# ATSAMA5D27WLSOM1 device description
Architecture: CORTEX-A5; Family: SAMA5; Series: SAMA5D2
Registers are 32-bit, read-write, no defined reset value unless marked. A register's access mark holds for its fields unless they carry their own. Offsets are from the block's base; [hi:lo] are bit positions; lines under a group give offsets from that group; {n}, {i} and the like mark numbered series; 'fields as' and 'values as' point back to an identical list.

## ISC — Image Sensor Controller
Instances: ISC 0xF0008000
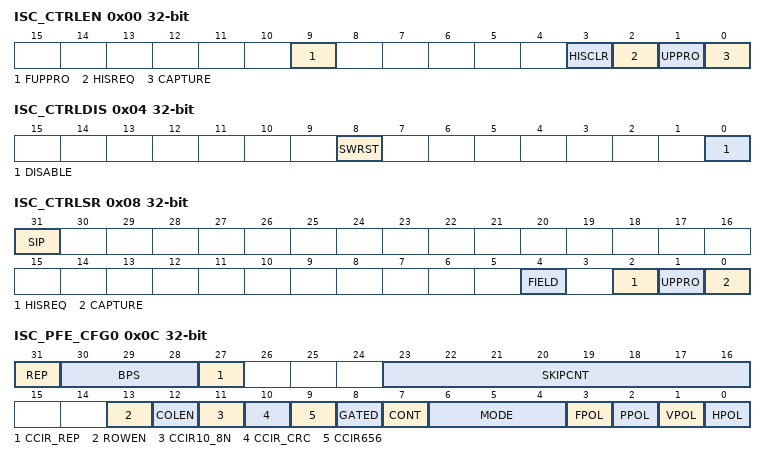
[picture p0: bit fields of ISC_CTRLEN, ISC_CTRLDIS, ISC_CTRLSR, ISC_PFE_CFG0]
0x00 ISC_CTRLEN wo — Control Enable Register
  [9] FUPPRO — Force Update Color Profile
  [3] HISCLR — Histogram Clear
  [2] HISREQ — Histogram Request
  [1] UPPRO — Update Profile
  [0] CAPTURE — Capture Input Stream Command
0x04 ISC_CTRLDIS wo — Control Disable Register
  [8] SWRST — Software Reset
  [0] DISABLE — Capture Disable
0x08 ISC_CTRLSR ro — Control Status Register
  [31] SIP — Synchronization In Progress
  [4] FIELD — Field Status (only relevant when the video stream is interlaced)
  [2] HISREQ — Histogram Request Pending
  [1] UPPRO — Profile Update Pending
  [0] CAPTURE — Capture pending
0x0C ISC_PFE_CFG0 — Parallel Front End Configuration 0 Register
  [31] REP — Up Multiply with Replication
  [30:28] BPS — Bits Per Sample
    0=TWELVE (12-bit input); 1=ELEVEN (11-bit input); 2=TEN (10-bit input); 3=NINE (9-bit input); 4=EIGHT (8-bit input)
  [27] CCIR_REP — CCIR Replication
  [23:16] SKIPCNT — Frame Skipping Counter
  [13] ROWEN — Row Cropping Enable
  [12] COLEN — Column Cropping Enable
  [11] CCIR10_8N — CCIR 10 bits or 8 bits
  [10] CCIR_CRC — CCIR656 CRC Decoder
  [9] CCIR656 — CCIR656 input mode
  [8] GATED — Gated input clock
  [7] CONT — Continuous Acquisition
  [6:4] MODE — Parallel Front End Mode
    0=PROGRESSIVE (Video source is progressive.); 1=DF_TOP (Video source is interlaced, two fields are captured starting with top field.); 2=DF_BOTTOM (Video source is interlaced, two fields are captured starting with bottom field.); 3=DF_IMMEDIATE (Video source is interlaced, two fields are captured immediately.); 4=SF_TOP (Video source is interlaced, one field is captured starting with the top field.); 5=SF_BOTTOM (Video source is interlaced, one field is captured starting with the bottom field.); 6=SF_IMMEDIATE (Video source is interlaced, one field is captured starting immediately.)
  [3] FPOL — Field Polarity
  [2] PPOL — Pixel Clock Polarity
  [1] VPOL — Vertical Synchronization Polarity
  [0] HPOL — Horizontal Synchronization Polarity
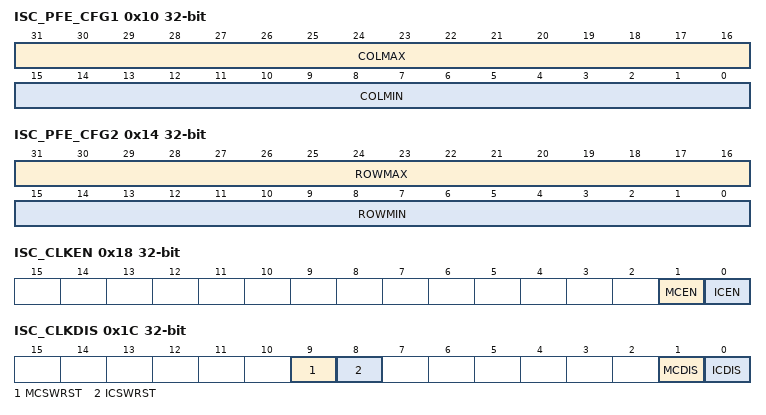
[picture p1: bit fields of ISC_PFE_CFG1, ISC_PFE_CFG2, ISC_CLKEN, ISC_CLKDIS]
0x10 ISC_PFE_CFG1 — Parallel Front End Configuration 1 Register
  [31:16] COLMAX — Column Maximum Limit
  [15:0] COLMIN — Column Minimum Limit
0x14 ISC_PFE_CFG2 — Parallel Front End Configuration 2 Register
  [31:16] ROWMAX — Row Maximum Limit
  [15:0] ROWMIN — Row Minimum Limit
0x18 ISC_CLKEN wo — Clock Enable Register
  [1] MCEN — Master Clock Enable
  [0] ICEN — ISP Clock Enable
0x1C ISC_CLKDIS wo — Clock Disable Register
  [9] MCSWRST — Master Clock Software Reset
  [8] ICSWRST — ISP Clock Software Reset
  [1] MCDIS — Master Clock Disable
  [0] ICDIS — ISP Clock Disable
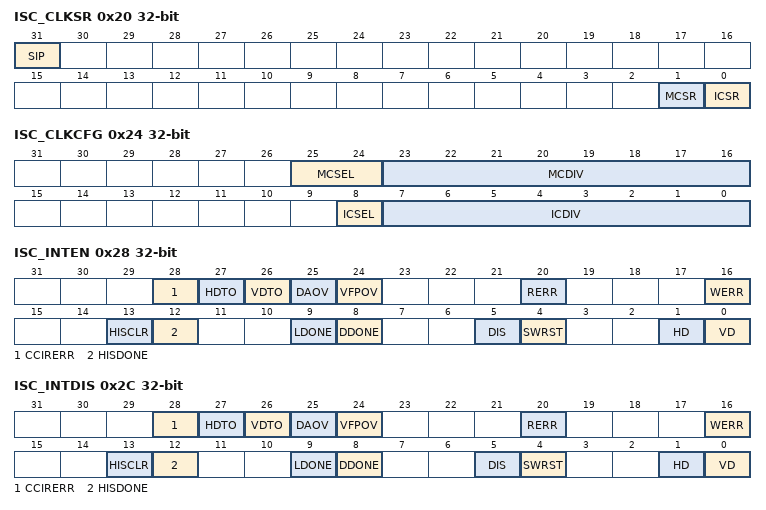
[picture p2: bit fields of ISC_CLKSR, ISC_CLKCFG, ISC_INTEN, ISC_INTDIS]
0x20 ISC_CLKSR ro — Clock Status Register
  [31] SIP — Synchronization In Progress
  [1] MCSR — Master Clock Status Register
  [0] ICSR — ISP Clock Status Register
0x24 ISC_CLKCFG — Clock Configuration Register
  [25:24] MCSEL — Master Clock Reference Clock Selection
  [23:16] MCDIV — Master Clock Divider
  [8] ICSEL — ISP Clock Selection
  [7:0] ICDIV — ISP Clock Divider
0x28 ISC_INTEN wo — Interrupt Enable Register
  [28] CCIRERR — CCIR Decoder Error Interrupt Enable
  [27] HDTO — Horizontal Synchronization Timeout Interrupt Enable
  [26] VDTO — Vertical Synchronization Timeout Interrupt Enable
  [25] DAOV — Data Overflow Interrupt Enable
  [24] VFPOV — Vertical Front Porch Overflow Interrupt Enable
  [20] RERR — Read Channel Error Interrupt Enable
  [16] WERR — Write Channel Error Interrupt Enable
  [13] HISCLR — Histogram Clear Interrupt Enable
  [12] HISDONE — Histogram Completed Interrupt Enable
  [9] LDONE — DMA List Done Interrupt Enable
  [8] DDONE — DMA Done Interrupt Enable
  [5] DIS — Disable Completed Interrupt Enable
  [4] SWRST — Software Reset Completed Interrupt Enable
  [1] HD — Horizontal Synchronization Detection Interrupt Enable
  [0] VD — Vertical Synchronization Detection Interrupt Enable
0x2C ISC_INTDIS wo — Interrupt Disable Register
  [28] CCIRERR — CCIR Decoder Error Interrupt Disable
  [27] HDTO — Horizontal Synchronization Timeout Interrupt Disable
  [26] VDTO — Vertical Synchronization Timeout Interrupt Disable
  [25] DAOV — Data Overflow Interrupt Disable
  [24] VFPOV — Vertical Front Porch Overflow Interrupt Disable
  [20] RERR — Read Channel Error Interrupt Disable
  [16] WERR — Write Channel Error Interrupt Disable
  [13] HISCLR — Histogram Clear Interrupt Disable
  [12] HISDONE — Histogram Completed Interrupt Disable
  [9] LDONE — DMA List Done Interrupt Disable
  [8] DDONE — DMA Done Interrupt Disable
  [5] DIS — Disable Completed Interrupt Disable
  [4] SWRST — Software Reset Completed Interrupt Disable
  [1] HD — Horizontal Synchronization Detection Interrupt Disable
  [0] VD — Vertical Synchronization Detection Interrupt Disable
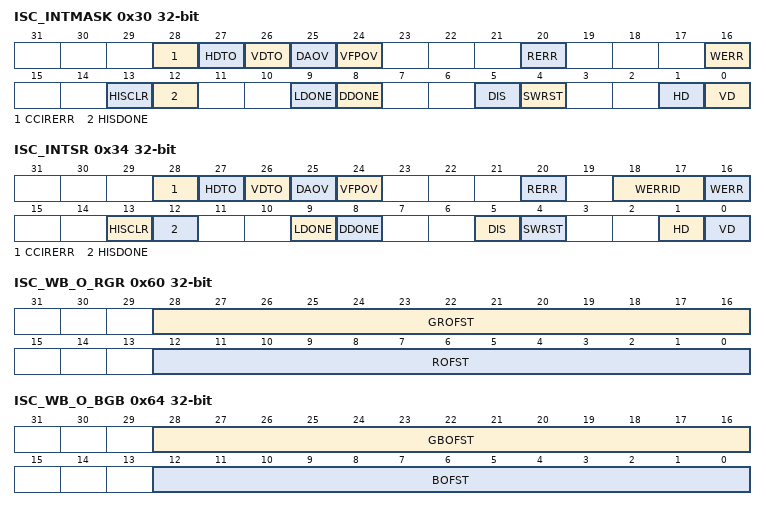
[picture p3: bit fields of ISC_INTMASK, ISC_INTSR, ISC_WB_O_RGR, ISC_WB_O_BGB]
0x30 ISC_INTMASK ro — Interrupt Mask Register
  [28] CCIRERR — CCIR Decoder Error Interrupt Mask
  [27] HDTO — Horizontal Synchronization Timeout Interrupt Mask
  [26] VDTO — Vertical Synchronization Timeout Interrupt Mask
  [25] DAOV — Data Overflow Interrupt Mask
  [24] VFPOV — Vertical Front Porch Overflow Interrupt Mask
  [20] RERR — Read Channel Error Interrupt Mask
  [16] WERR — Write Channel Error Interrupt Mask
  [13] HISCLR — Histogram Clear Interrupt Mask
  [12] HISDONE — Histogram Completed Interrupt Mask
  [9] LDONE — DMA List Done Interrupt Mask
  [8] DDONE — DMA Done Interrupt Mask
  [5] DIS — Disable Completed Interrupt Mask
  [4] SWRST — Software Reset Completed Interrupt Mask
  [1] HD — Horizontal Synchronization Detection Interrupt Mask
  [0] VD — Vertical Synchronization Detection Interrupt Mask
0x34 ISC_INTSR ro — Interrupt Status Register
  [28] CCIRERR — CCIR Decoder Error Interrupt
  [27] HDTO — Horizontal Synchronization Timeout Interrupt
  [26] VDTO — Vertical Synchronization Timeout Interrupt
  [25] DAOV — Data Overflow Interrupt
  [24] VFPOV — Vertical Front Porch Overflow Interrupt
  [20] RERR — Read Channel Error Interrupt
  [18:17] WERRID — Write Channel Error Identifier
    0=CH0 (An error occurred for Channel 0 (RAW/RGB/Y)); 1=CH1 (An error occurred for Channel 1 (CbCr/Cb)); 2=CH2 (An error occurred for Channel 2 (Cr)); 3=WB (Write back channel error)
  [16] WERR — Write Channel Error Interrupt
  [13] HISCLR — Histogram Clear Interrupt
  [12] HISDONE — Histogram Completed Interrupt
  [9] LDONE — DMA List Done Interrupt
  [8] DDONE — DMA Done Interrupt
  [5] DIS — Disable Completed Interrupt
  [4] SWRST — Software Reset Completed Interrupt
  [1] HD — Horizontal Synchronization Detected Interrupt
  [0] VD — Vertical Synchronization Detected Interrupt
0x58 ISC_WB_CTRL — White Balance Control Register
  [0] ENABLE — White Balance Enable
0x5C ISC_WB_CFG — White Balance Configuration Register
  [1:0] BAYCFG — White Balance Bayer Configuration (Pixel Color Pattern)
    0=GRGR (Starting Row configuration is G R G R (Red Row)); 1=RGRG (Starting Row configuration is R G R G (Red Row)); 2=GBGB (Starting Row configuration is G B G B (Blue Row)); 3=BGBG (Starting Row configuration is B G B G (Blue Row))
0x60 ISC_WB_O_RGR — White Balance Offset for R, GR Register
  [28:16] GROFST — Offset Green Component for Red Row (signed 13 bits 1:12:0)
  [12:0] ROFST — Offset Red Component (signed 13 bits 1:12:0)
0x64 ISC_WB_O_BGB — White Balance Offset for B, GB Register
  [28:16] GBOFST — Offset Green Component for Blue Row (signed 13 bits, 1:12:0)
  [12:0] BOFST — Offset Blue Component (signed 13 bits, 1:12:0)
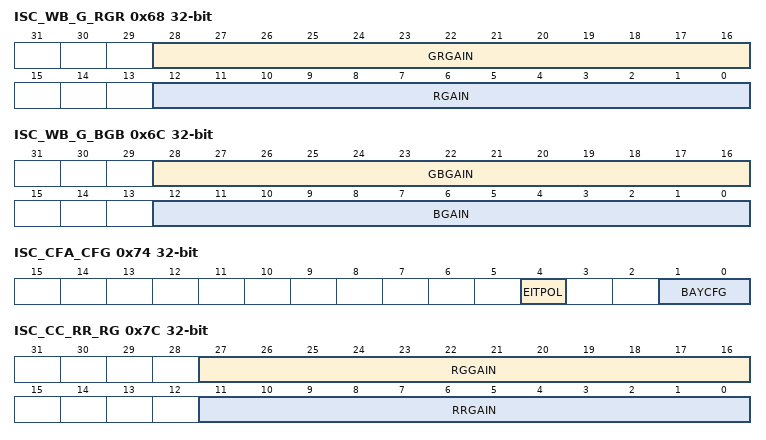
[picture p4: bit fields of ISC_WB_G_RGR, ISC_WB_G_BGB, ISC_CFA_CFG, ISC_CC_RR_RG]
0x68 ISC_WB_G_RGR — White Balance Gain for R, GR Register
  [28:16] GRGAIN — Green Component (Red row) Gain (unsigned 13 bits, 0:4:9)
  [12:0] RGAIN — Red Component Gain (unsigned 13 bits, 0:4:9)
0x6C ISC_WB_G_BGB — White Balance Gain for B, GB Register
  [28:16] GBGAIN — Green Component (Blue row) Gain (unsigned 13 bits, 0:4:9)
  [12:0] BGAIN — Blue Component Gain (unsigned 13 bits, 0:4:9)
0x70 ISC_CFA_CTRL — Color Filter Array Control Register
  [0] ENABLE — Color Filter Array Interpolation Enable
0x74 ISC_CFA_CFG — Color Filter Array Configuration Register
  [4] EITPOL — Edge Interpolation
  [1:0] BAYCFG — Color Filter Array Pattern
    0=GRGR (Starting row configuration is G R G R (red row)); 1=RGRG (Starting row configuration is R G R G (red row); 2=GBGB (Starting row configuration is G B G B (blue row)); 3=BGBG (Starting row configuration is B G B G (blue row))
0x78 ISC_CC_CTRL — Color Correction Control Register
  [0] ENABLE — Color Correction Enable
0x7C ISC_CC_RR_RG — Color Correction RR RG Register
  [27:16] RGGAIN — Green Gain for Red Component (signed 12 bits, 1:3:8)
  [11:0] RRGAIN — Red Gain for Red Component (signed 12 bits, 1:3:8)
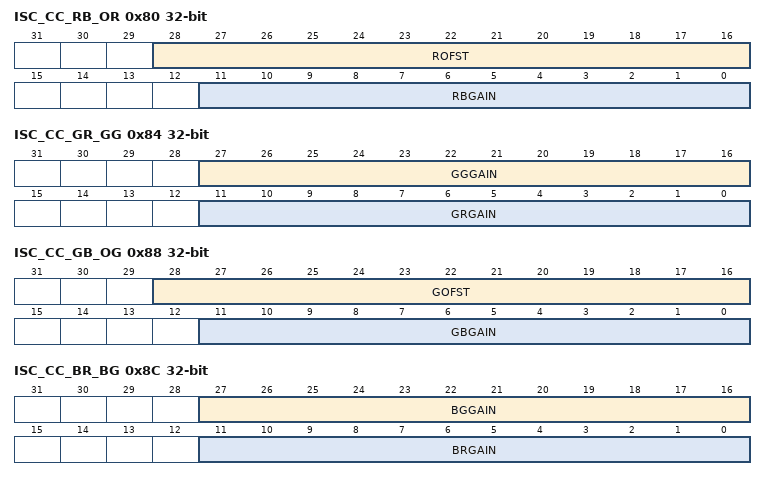
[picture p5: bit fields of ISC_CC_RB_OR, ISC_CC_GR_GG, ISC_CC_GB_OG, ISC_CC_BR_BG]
0x80 ISC_CC_RB_OR — Color Correction RB OR Register
  [28:16] ROFST — Red Component Offset (signed 13 bits, 1:12:0)
  [11:0] RBGAIN — Blue Gain for Red Component (signed 12 bits, 1:3:8)
0x84 ISC_CC_GR_GG — Color Correction GR GG Register
  [27:16] GGGAIN — Green Gain for Green Component (signed 12 bits, 1:3:8)
  [11:0] GRGAIN — Red Gain for Green Component (signed 12 bits, 1:3:8)
0x88 ISC_CC_GB_OG — Color Correction GB OG Register
  [28:16] GOFST — Green Component Offset (signed 13 bits, 1:12:0)
  [11:0] GBGAIN — Blue Gain for Green Component (signed 12 bits, 1:3:8)
0x8C ISC_CC_BR_BG — Color Correction BR BG Register
  [27:16] BGGAIN — Green Gain for Blue Component (signed 12 bits, 1:3:8)
  [11:0] BRGAIN — Red Gain for Blue Component (signed 12 bits, 1:3:8)
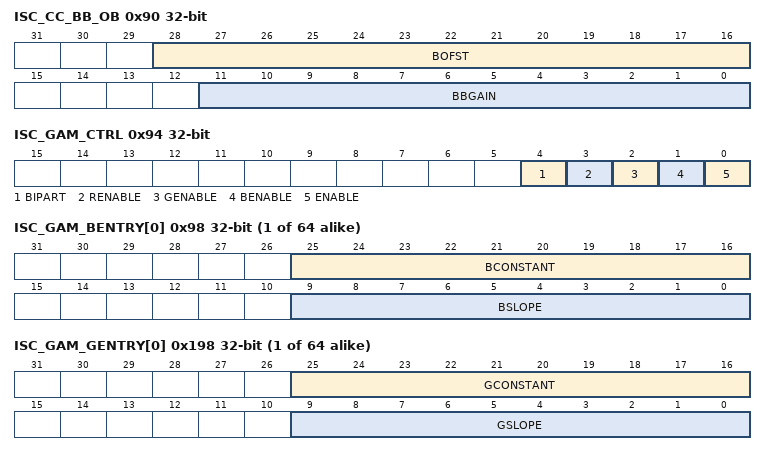
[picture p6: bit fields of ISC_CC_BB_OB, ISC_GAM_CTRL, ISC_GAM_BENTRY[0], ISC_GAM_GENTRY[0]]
0x90 ISC_CC_BB_OB — Color Correction BB OB Register
  [28:16] BOFST — Blue Component Offset (signed 13 bits, 1:12:0)
  [11:0] BBGAIN — Blue Gain for Blue Component (signed 12 bits, 1:3:8)
0x94 ISC_GAM_CTRL — Gamma Correction Control Register
  [4] BIPART — Bipartite Table Configuration
  [3] RENABLE — Gamma Correction Enable for R Channel
  [2] GENABLE — Gamma Correction Enable for G Channel
  [1] BENABLE — Gamma Correction Enable for B Channel
  [0] ENABLE — Gamma Correction Enable
{0x98+4i} ISC_GAM_BENTRY[{i}] (i=0..63) — Gamma Correction Blue Entry
  [25:16] BCONSTANT — Blue Color Constant for Piecewise Interpolation (unsigned 10 bits 0:10:0)
  [9:0] BSLOPE — Blue Color Slope for Piecewise Interpolation (signed 10 bits 1:3:6)
{0x198+4i} ISC_GAM_GENTRY[{i}] (i=0..63) — Gamma Correction Green Entry
  [25:16] GCONSTANT — Green Color Constant for Piecewise Interpolation (unsigned 10 bits 0:10:0)
  [9:0] GSLOPE — Green Color Slope for Piecewise Interpolation (signed 10 bits 1:3:6)
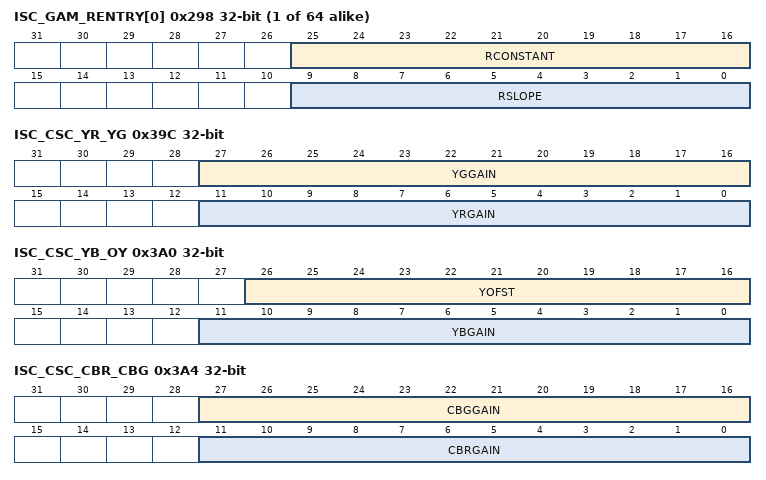
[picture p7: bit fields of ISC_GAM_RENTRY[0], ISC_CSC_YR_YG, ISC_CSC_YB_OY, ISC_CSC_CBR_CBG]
{0x298+4i} ISC_GAM_RENTRY[{i}] (i=0..63) — Gamma Correction Red Entry
  [25:16] RCONSTANT — Red Color Constant for Piecewise Interpolation (unsigned 10 bits 0:10:0)
  [9:0] RSLOPE — Red Color Slope for Piecewise Interpolation (signed 10 bits 1:3:6)
0x398 ISC_CSC_CTRL — Color Space Conversion Control Register
  [0] ENABLE — RGB to YCbCr Color Space Conversion Enable
0x39C ISC_CSC_YR_YG — Color Space Conversion YR, YG Register
  [27:16] YGGAIN — Green Gain for Luminance (signed 12 bits 1:3:8)
  [11:0] YRGAIN — Reg Gain for Luminance (signed 12 bits 1:3:8)
0x3A0 ISC_CSC_YB_OY — Color Space Conversion YB, OY Register
  [26:16] YOFST — Luminance Offset (11 bits signed 1:10:0)
  [11:0] YBGAIN — Blue Gain for Luminance Component (12 bits signed 1:3:8)
0x3A4 ISC_CSC_CBR_CBG — Color Space Conversion CBR CBG Register
  [27:16] CBGGAIN — Green Gain for Blue Chrominance (signed 12 bits 1:3:8)
  [11:0] CBRGAIN — Red Gain for Blue Chrominance (signed 12 bits, 1:3:8)
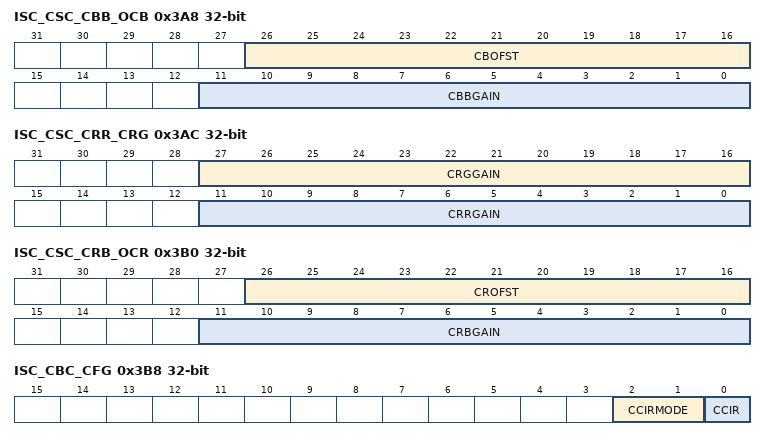
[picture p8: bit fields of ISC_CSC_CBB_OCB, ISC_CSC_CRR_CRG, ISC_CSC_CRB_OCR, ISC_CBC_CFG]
0x3A8 ISC_CSC_CBB_OCB — Color Space Conversion CBB OCB Register
  [26:16] CBOFST — Blue Chrominance Offset (signed 11 bits 1:10:0)
  [11:0] CBBGAIN — Blue Gain for Blue Chrominance (signed 12 bits 1:3:8)
0x3AC ISC_CSC_CRR_CRG — Color Space Conversion CRR CRG Register
  [27:16] CRGGAIN — Green Gain for Red Chrominance (signed 12 bits 1:3:8)
  [11:0] CRRGAIN — Red Gain for Red Chrominance (signed 12 bits 1:3:8)
0x3B0 ISC_CSC_CRB_OCR — Color Space Conversion CRB OCR Register
  [26:16] CROFST — Red Chrominance Offset (signed 11 bits 1:10:0)
  [11:0] CRBGAIN — Blue Gain for Red Chrominance (signed 12 bits 1:3:8)
0x3B4 ISC_CBC_CTRL — Contrast and Brightness Control Register
  [0] ENABLE — Contrast and Brightness Control Enable
0x3B8 ISC_CBC_CFG — Contrast and Brightness Configuration Register
  [2:1] CCIRMODE — CCIR656 Byte Ordering
    0=CBY (Byte ordering Cb0, Y0, Cr0, Y1); 1=CRY (Byte ordering Cr0, Y0, Cb0, Y1); 2=YCB (Byte ordering Y0, Cb0, Y1, Cr0); 3=YCR (Byte ordering Y0, Cr0, Y1, Cb0)
  [0] CCIR — CCIR656 Stream Enable
0x3BC ISC_CBC_BRIGHT — Contrast and Brightness, Brightness Register
  [10:0] BRIGHT — Brightness Control (signed 11 bits 1:10:0)
0x3C0 ISC_CBC_CONTRAST — Contrast and Brightness, Contrast Register
  [11:0] CONTRAST — Contrast (unsigned 12 bits 0:4:8)
0x3C4 ISC_SUB422_CTRL — Subsampling 4:4:4 to 4:2:2 Control Register
  [0] ENABLE — 4:4:4 to 4:2:2 Chrominance Horizontal Subsampling Filter Enable
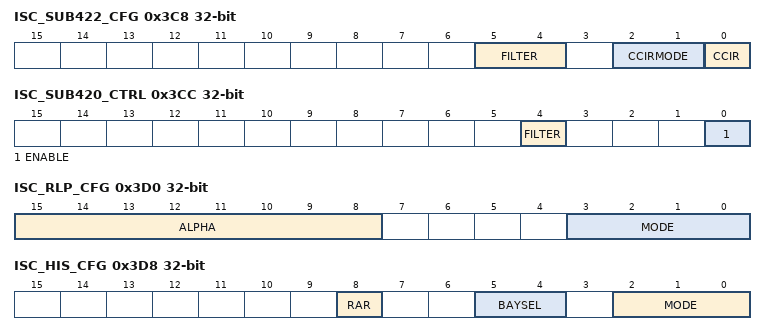
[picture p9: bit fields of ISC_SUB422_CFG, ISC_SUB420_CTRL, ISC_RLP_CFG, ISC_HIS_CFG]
0x3C8 ISC_SUB422_CFG — Subsampling 4:4:4 to 4:2:2 Configuration Register
  [5:4] FILTER — Low Pass Filter Selection
    0=FILT0CO (Cosited, {1}); 1=FILT1CE (Centered {1, 1}); 2=FILT2CO (Cosited {1,2,1}); 3=FILT3CE (Centered {1, 3, 3, 1})
  [2:1] CCIRMODE — CCIR656 Byte Ordering
    values as ISC_CBC_CFG.CCIRMODE
  [0] CCIR — CCIR656 Input Stream
0x3CC ISC_SUB420_CTRL — Subsampling 4:2:2 to 4:2:0 Control Register
  [4] FILTER — Interlaced or Progressive Chrominance Filter
  [0] ENABLE — 4:2:2 to 4:2:0 Vertical Subsampling Filter Enable (Center Aligned)
0x3D0 ISC_RLP_CFG — Rounding, Limiting and Packing Configuration Register
  [15:8] ALPHA — Alpha Value for Alpha-enabled RGB Mode
  [3:0] MODE — Rounding, Limiting and Packing Mode
    {v}=DAT{v+8} ({v+8}-bit data) (v=0..4); 5=DATY8 (8-bit luminance only); 6=DATY10 (10-bit luminance only); 7=ARGB444 (12-bit RGB+4-bit Alpha (MSB)); 8=ARGB555 (15-bit RGB+1-bit Alpha (MSB)); 9=RGB565 (16-bit RGB); 10=ARGB32 (24-bits RGB mode+8-bit Alpha); 11=YYCC (YCbCr mode (full range, [0-255])); 12=YYCC_LIMITED (YCbCr mode (limited range))
0x3D4 ISC_HIS_CTRL — Histogram Control Register
  [0] ENABLE — Histogram Sub Module Enable
0x3D8 ISC_HIS_CFG — Histogram Configuration Register
  [8] RAR — Histogram Reset After Read
  [5:4] BAYSEL — Bayer Color Component Selection
    0=GRGR (Starting row configuration is G R G R (red row)); 1=RGRG (Starting row configuration is R G R G (red row)); 2=GBGB (Starting row configuration is G B G B (blue row); 3=BGBG (Starting row configuration is B G B G (blue row))
  [2:0] MODE — Histogram Operating Mode
    0=Gr (Gr sampling); 1=R (R sampling); 2=Gb (Gb sampling); 3=B (B sampling); 4=Y (Luminance-only mode); 5=RAW (Raw sampling); 6=YCCIR656 (Luminance only with CCIR656 10-bit or 8-bit mode)
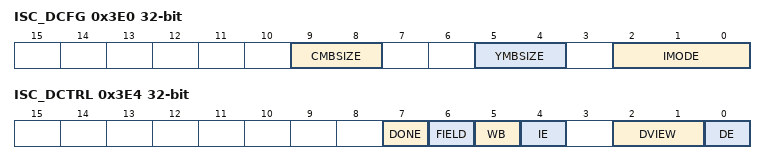
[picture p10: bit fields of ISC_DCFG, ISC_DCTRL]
0x3E0 ISC_DCFG — DMA Configuration Register
  [9:8] CMBSIZE — DMA Memory Burst Size C channel
    0=SINGLE (DMA single access); 1=BEATS4 (4-beat burst access); 2=BEATS8 (8-beat burst access); 3=BEATS16 (16-beat burst access)
  [5:4] YMBSIZE — DMA Memory Burst Size Y channel
    values as CMBSIZE
  [2:0] IMODE — DMA Input Mode Selection
    0=PACKED8 (8 bits, single channel packed); 1=PACKED16 (16 bits, single channel packed); 2=PACKED32 (32 bits, single channel packed); 3=YC422SP (32 bits, dual channel); 4=YC422P (32 bits, triple channel); 5=YC420SP (32 bits, dual channel); 6=YC420P (32 bits, triple channel)
0x3E4 ISC_DCTRL — DMA Control Register
  [7] DONE — Descriptor Processing Status(2)
  [6] FIELD — Value of Captured Frame Field Signal(1)(2)
  [5] WB — Write Back Operation Enable
  [4] IE — Interrupt Enable
  [2:1] DVIEW — Descriptor View
    0=PACKED (Address {0} Stride {0} are updated); 1=SEMIPLANAR (Address {0,1} Stride {0,1} are updated); 2=PLANAR (Address {0,1,2} Stride {0,1,2} are updated)
  [0] DE — Descriptor Enable
0x3E8 ISC_DNDA — DMA Descriptor Address Register
  [31:2] NDA — Next Descriptor Address Register
{0x3EC+8i} ISC_SUB0[{i}] (i=0..2) group
  0x00 ISC_DAD — DMA Address Register
    [31:0] AD0 — Channel Address
  0x04 ISC_DST — DMA Stride Register
    [15:0] ST0 — Channel Stride
{0x410+4i} ISC_HIS_ENTRY[{i}] (i=0..511) ro — Histogram Entry
  [19:0] COUNT — Entry Counter
